VERSION ""

NS_ :

BS_:

BU_:

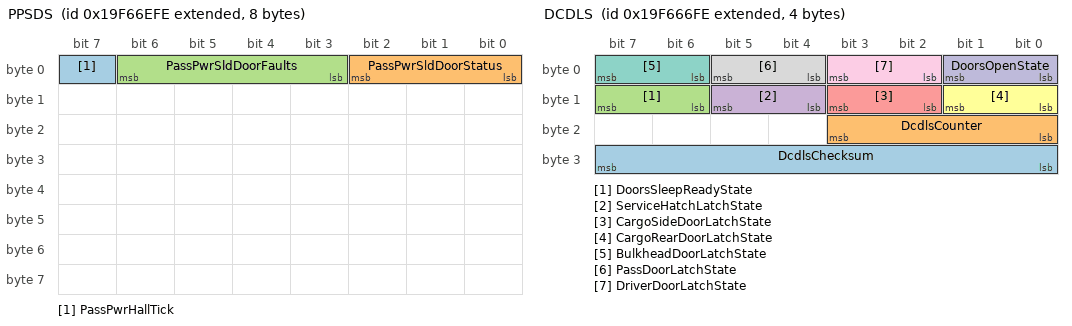
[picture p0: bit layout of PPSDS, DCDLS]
BO_ 2583064318 PPSDS: 8 Vector__XXX
 SG_ PassPwrHallTick : 7|1@1+ (1,0) [0|1] "" Vector__XXX
 SG_ PassPwrSldDoorStatus : 0|3@1+ (1,0) [0|0] "" Vector__XXX
 SG_ PassPwrSldDoorFaults : 3|4@1+ (1,0) [0|15] "" Vector__XXX

BO_ 2583062270 DCDLS: 4 Vector__XXX
 SG_ DcdlsChecksum : 24|8@1+ (1,0) [0|255] "" Vector__XXX
 SG_ DcdlsCounter : 16|4@1+ (1,0) [0|15] "" Vector__XXX
 SG_ DoorsSleepReadyState : 14|2@1+ (1,0) [0|3] "-" Vector__XXX
 SG_ ServiceHatchLatchState : 12|2@1+ (1,0) [0|3] "" Vector__XXX
 SG_ CargoSideDoorLatchState : 10|2@1+ (1,0) [0|3] "-" Vector__XXX
 SG_ CargoRearDoorLatchState : 8|2@1+ (1,0) [0|3] "-" Vector__XXX
 SG_ BulkheadDoorLatchState : 6|2@1+ (1,0) [0|3] "-" Vector__XXX
 SG_ PassDoorLatchState : 4|2@1+ (1,0) [0|3] "-" Vector__XXX
 SG_ DriverDoorLatchState : 2|2@1+ (1,0) [0|3] "-" Vector__XXX
 SG_ DoorsOpenState : 0|2@1+ (1,0) [0|3] "-" Vector__XXX

CM_ "$File: //depot/auto/dbc/Software_Modules/Closures_System/CabinDoors/0.2.2.0/CabinDoors.dbc $
$Change: 215968 $
$DateTime: 2024/08/21 09:56:34 $
$Revision: #1 $";
CM_ SG_ 2583062270 DoorsSleepReadyState "The status of all vehicle doors ";
CM_ SG_ 2583062270 CargoSideDoorLatchState "Actual state of the door latch";
CM_ SG_ 2583062270 CargoRearDoorLatchState "Actual state of the door latch";
CM_ SG_ 2583062270 BulkheadDoorLatchState "Actual state of the door latch";
CM_ SG_ 2583062270 PassDoorLatchState "Actual state of the door latch";
CM_ SG_ 2583062270 DriverDoorLatchState "Actual state of the door latch";
CM_ SG_ 2583062270 DoorsOpenState "The status of all vehicle doors ";
BA_DEF_ SG_  "SigType" ENUM  "Default","Range","RangeSigned","ASCII","Discrete","Control","ReferencePGN","DTC","StringDelimiter","StringLength","StringLengthControl","MessageCounter","MessageChecksum";
BA_DEF_ SG_  "GenSigEVName" STRING ;
BA_DEF_ SG_  "GenSigILSupport" ENUM  "No","Yes";
BA_DEF_ SG_  "GenSigSendType" ENUM  "Cyclic","OnWrite","OnWriteWithRepetition","OnChange","OnChangeWithRepetition","IfActive","IfActiveWithRepetition","NoSigSendType";
BA_DEF_ BO_  "SendOnChange" ENUM  "No","Yes";
BA_DEF_ SG_  "GenSigStartValue" INT 0 2147483647;
BA_DEF_ BO_  "GenMsgDelayTime" INT 0 1000;
BA_DEF_ BO_  "GenMsgILSupport" ENUM  "No","Yes";
BA_DEF_ BU_  "NmStationAddress" INT 0 255;
BA_DEF_ BO_  "GenMsgSendType" ENUM  "cyclic","NotUsed","IfActive","NotUsed","NotUsed","NotUsed","NotUsed","NotUsed","noMsgSendType";
BA_DEF_ BO_  "GenMsgRequestable" INT 0 1;
BA_DEF_ BO_  "GenMsgCycleTime" INT 0 3600000;
BA_DEF_  "DBName" STRING ;
BA_DEF_  "BusType" STRING ;
BA_DEF_  "ProtocolType" STRING ;
BA_DEF_ BO_  "VFrameFormat" ENUM  "StandardCAN","ExtendedCAN","reserved","J1939PG";
BA_DEF_ BO_  "Producer" STRING ;
BA_DEF_DEF_  "SigType" "Default";
BA_DEF_DEF_  "GenSigEVName" "Env@Nodename_@Signame";
BA_DEF_DEF_  "GenSigILSupport" "Yes";
BA_DEF_DEF_  "GenSigSendType" "NoSigSendType";
BA_DEF_DEF_  "SendOnChange" "No";
BA_DEF_DEF_  "GenSigStartValue" 0;
BA_DEF_DEF_  "GenMsgDelayTime" 0;
BA_DEF_DEF_  "GenMsgILSupport" "Yes";
BA_DEF_DEF_  "NmStationAddress" 254;
BA_DEF_DEF_  "GenMsgSendType" "noMsgSendType";
BA_DEF_DEF_  "GenMsgRequestable" 1;
BA_DEF_DEF_  "GenMsgCycleTime" 0;
BA_DEF_DEF_  "DBName" "";
BA_DEF_DEF_  "BusType" "CAN";
BA_DEF_DEF_  "ProtocolType" "J1939";
BA_DEF_DEF_  "VFrameFormat" "J1939PG";
BA_DEF_DEF_  "Producer" "";
BA_ "DBName" "CBDRS";
BA_ "GenMsgCycleTime" BO_ 2583064318 100;
BA_ "Producer" BO_ 2583062270 "CLS";
BA_ "GenMsgDelayTime" BO_ 2583062270 100;
BA_ "SendOnChange" BO_ 2583062270 1;
BA_ "GenMsgSendType" BO_ 2583062270 0;
BA_ "GenMsgCycleTime" BO_ 2583062270 1000;
BA_ "SigType" SG_ 2583062270 DcdlsChecksum 12;
BA_ "SigType" SG_ 2583062270 DcdlsCounter 11;
VAL_ 2583064318 PassPwrSldDoorStatus 7 "Not available" 6 "Error" 5 "Unknown" 4 "Closing" 3 "Opening" 2 "Intermediate" 1 "Closed" 0 "Open" ;
VAL_ 2583064318 PassPwrSldDoorFaults 8 "UnknownPosition" 7 "CalibrationFail" 6 "etc" 5 "Undervoltage" 4 "Overvoltage" 3 "Motor Overload" 2 "Movement interrupted" 1 "No Fault" 0 "NA" ;
VAL_ 2583062270 DoorsSleepReadyState 3 "Not Available" 1 "All doors standstill" 0 "Any door moving" ;
VAL_ 2583062270 ServiceHatchLatchState 3 "NA" 2 "Fault" 1 "Open" 0 "Closed" ;
VAL_ 2583062270 CargoSideDoorLatchState 3 "Not Available" 2 "Error" 1 "Latched" 0 "Unlatched" ;
VAL_ 2583062270 CargoRearDoorLatchState 3 "Not Available" 2 "Error" 1 "Latched" 0 "Unlatched" ;
VAL_ 2583062270 BulkheadDoorLatchState 3 "Not Available" 2 "Error" 1 "Latched" 0 "Unlatched" ;
VAL_ 2583062270 PassDoorLatchState 3 "Not Available" 2 "Error" 1 "Latched" 0 "Unlatched" ;
VAL_ 2583062270 DriverDoorLatchState 3 "Not Available" 2 "Error" 1 "Latched" 0 "Unlatched" ;
VAL_ 2583062270 DoorsOpenState 3 "Not Available" 2 "Error" 1 "All doors closed" 0 "Any door opened" ;
